# SGPIO3 register map
Registers from a debugger description file.
Registers are 32-bit, access not given, no defined reset value unless marked. A register's access mark holds for its fields unless they carry their own. Addresses are absolute; registers are grouped by the start of their names; lines under a group give offsets from that group; [hi:lo] are bit positions; {n}, {i} and the like mark numbered series; 'fields as' and 'values as' point back to an identical list; <NAME> marks a mode.

## SGPIO3
0x5000E000 SGPIO3/Input ro
  [31:0] Input
0x5000E004 SGPIO3/Output
  [31:0] Output
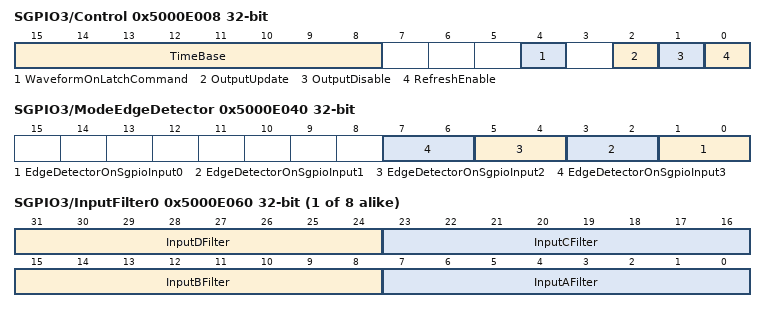
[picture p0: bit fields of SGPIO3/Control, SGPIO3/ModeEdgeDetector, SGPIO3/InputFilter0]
0x5000E008 SGPIO3/Control
  [15:8] TimeBase, [4] WaveformOnLatchCommand, [2] OutputUpdate, [1] OutputDisable, [0] RefreshEnable
0x5000E040 SGPIO3/ModeEdgeDetector
  [2n+1:2n] EdgeDetectorOnSgpioInput{n} (n=0..3)
0x5000E044 SGPIO3/StatusInt0
  [3:0] StatusInt0
0x5000E048 SGPIO3/StatusInt1
  [3:0] StatusInt1
0x5000E04C SGPIO3/MaskInt
  [3:0] MaskInt
0x5000E050 SGPIO3/ClearInt
  [3:0] ClearInt
0x5000E054 SGPIO3/InputUpdate
  [31:0] InputUpdate
{0x5000E060+4i} SGPIO3/InputFilter{i} (i=0..7)
  [31:24] InputDFilter, [23:16] InputCFilter, [15:8] InputBFilter, [7:0] InputAFilter
